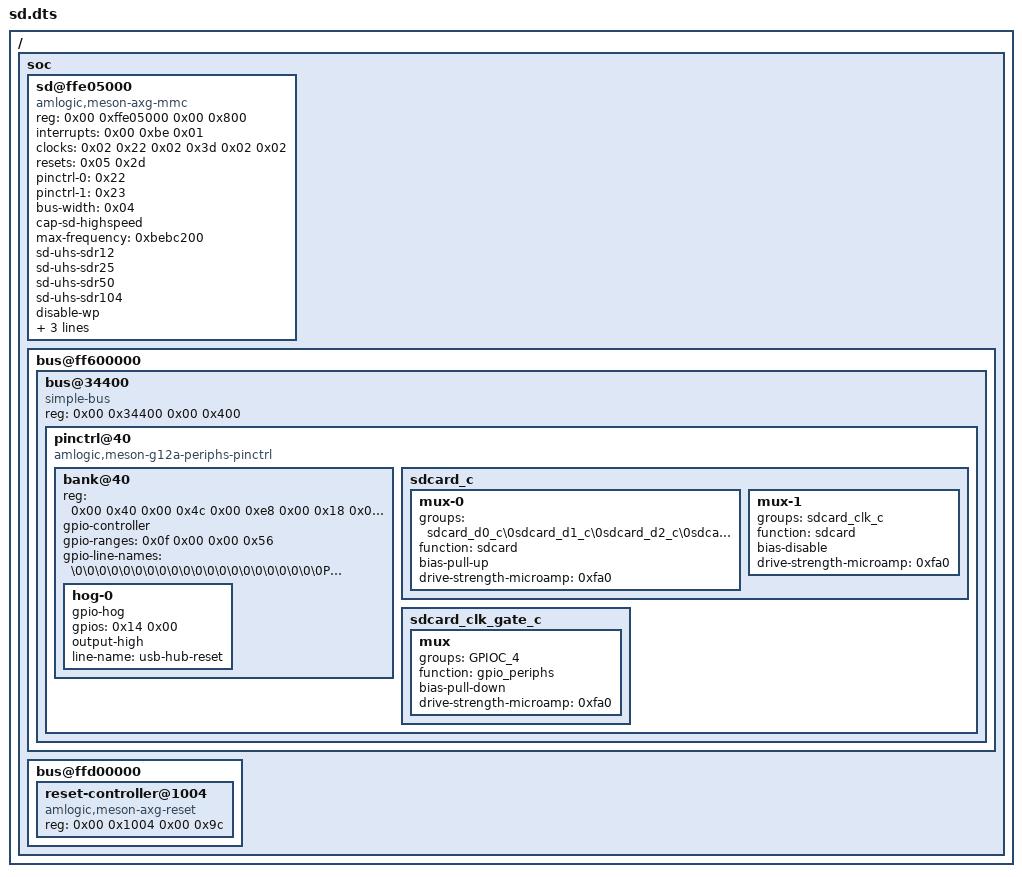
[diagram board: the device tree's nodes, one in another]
/ {
	soc {
        /delete-node/ bus@ffd00000;

        sd@ffe05000 {
            compatible = "amlogic,meson-axg-mmc";
            reg = <0x00 0xffe05000 0x00 0x800>;
            interrupts = <0x00 0xbe 0x01>;
            status = "okay";
            clocks = <0x02 0x22 0x02 0x3d 0x02 0x02>;
            clock-names = "core\0clkin0\0clkin1";
            resets = <0x05 0x2d>;
            pinctrl-0 = <0x22>;
            pinctrl-1 = <0x23>;
            pinctrl-names = "default\0clk-gate";
            bus-width = <0x04>;
            cap-sd-highspeed;
            max-frequency = <0xbebc200>;
            sd-uhs-sdr12;
            sd-uhs-sdr25;
            sd-uhs-sdr50;
            sd-uhs-sdr104;
            disable-wp;
            cd-gpios = <0x14 0x2f 0x01>;
            vmmc-supply = <0x24>;
            vqmmc-supply = <0x25>;
        };

        bus@ff600000 {
            bus@34400 {
                compatible = "simple-bus";
                reg = <0x00 0x34400 0x00 0x400>;
                #address-cells = <0x02>;
                #size-cells = <0x02>;
                ranges = <0x00 0x00 0x00 0x34400 0x00 0x400>;

                pinctrl@40 {
                    compatible = "amlogic,meson-g12a-periphs-pinctrl";
                    #address-cells = <0x02>;
                    #size-cells = <0x02>;
                    ranges;
                    phandle = <0x0f>;

                    bank@40 {
                        reg = <0x00 0x40 0x00 0x4c 0x00 0xe8 0x00 0x18 0x00 0x120 0x00 0x18 0x00 0x2c0 0x00 0x40 0x00 0x340 0x00 0x1c>;
                        reg-names = "gpio\0pull\0pull-enable\0mux\0ds";
                        gpio-controller;
                        #gpio-cells = <0x02>;
                        gpio-ranges = <0x0f 0x00 0x00 0x56>;
                        gpio-line-names = "\0\0\0\0\0\0\0\0\0\0\0\0\0\0\0\0\0\0\0\0\0PIN_36\0PIN_26\0PIN_32\0\0\0\0\0\0\0\0\0\0\0\0\0\0\0\0\0\0\0\0\0\0\0\0\0\0\0\0\0\0\0\0\0\0\0\0\0\0\0\0PIN_27\0PIN_28\0PIN_16\0PIN_18\0PIN_22\0PIN_11\0PIN_13\0PIN_7\0PIN_33\0PIN_15\0PIN_19\0PIN_21\0PIN_24\0PIN_23\0PIN_8\0PIN_10\0PIN_29\0PIN_31\0PIN_12\0PIN_3\0PIN_5\0PIN_35";
                        phandle = <0x14>;

                        hog-0 {
                            gpio-hog;
                            gpios = <0x14 0x00>;
                            output-high;
                            line-name = "usb-hub-reset";
                        };
                    };
                
                    sdcard_c {
                        phandle = <0x22>;

                        mux-0 {
                            groups = "sdcard_d0_c\0sdcard_d1_c\0sdcard_d2_c\0sdcard_d3_c\0sdcard_cmd_c";
                            function = "sdcard";
                            bias-pull-up;
                            drive-strength-microamp = <0xfa0>;
                        };

                        mux-1 {
                            groups = "sdcard_clk_c";
                            function = "sdcard";
                            bias-disable;
                            drive-strength-microamp = <0xfa0>;
                        };
                    };

                    sdcard_clk_gate_c {
                        phandle = <0x23>;

                        mux {
                            groups = "GPIOC_4";
                            function = "gpio_periphs";
                            bias-pull-down;
                            drive-strength-microamp = <0xfa0>;
                        };
                    };
                };
            };            
        };

        bus@ffd00000 {
            reset-controller@1004 {
				compatible = "amlogic,meson-axg-reset";
				reg = <0x00 0x1004 0x00 0x9c>;
				#reset-cells = <0x01>;
				phandle = <0x05>;
			};
        };
    };
};
